# N571P032_v3 register map
File version: 1.0
Registers are 32-bit, read-write, reset 0x0 unless marked. A register's access mark holds for its fields unless they carry their own. Offsets are from the block's base; [hi:lo] are bit positions; {n}, {i} and the like mark numbered series.

## RTC — RTC Register Map
Base 0x40008000
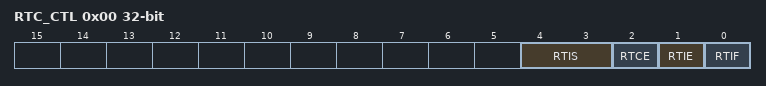
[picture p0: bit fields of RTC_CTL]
0x00 RTC_CTL — RTC Control Register
  [4:3] RTIS — RTC Timer Interval Select. These two bits select the timeout interval for the RTC.
    0=Time-out frequency is 0.25Hz,; 1=Time-out frequency is 2Hz,; 2=Time-out frequency is 8Hz,; 3=Time-out frequency is 32Hz
  [2] RTCE — RTC Enable
    0=Disable RTC function; 1=Enable RTC function
  [1] RTIE — RTC Interrupt Enable
    0=Disable the RTC interrupt; 1=Enable the RTC interrupt
  [0] RTIF — RTC Interrupt Flag. If the RTC interrupt is enabled, then the hardware will set this bit to indicate that the RTC interrupt has occurred. If the RTC interrupt is not enabled, then this bit indicates that a timeout period has elapsed. Note: This bit is cleared by writing 1 to this bit.
    0=RTC interrupt does not occur; 1=RTC interrupt occurs

## TMR — TMR Register Map
Base 0x40010000
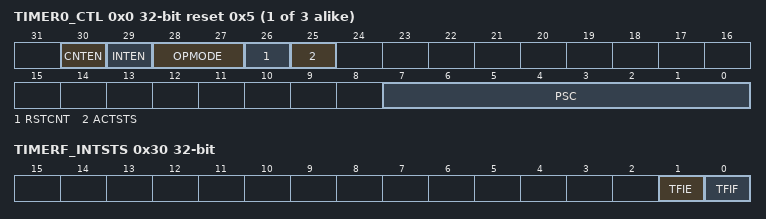
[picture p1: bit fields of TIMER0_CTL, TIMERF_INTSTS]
{0x0+0x20*i} TIMER{i}_CTL reset 0x5 (i=0..2) — Timer0 Control and Status Register
  [30] CNTEN — Counter Enable Bit
    0=Stop/Suspend counting; 1=Start counting
  [29] INTEN — Interrupt Enable Bit. If timer interrupt is enabled, the timer asserts its interrupt signal when the associated count is equal to TIMERx_CMP.
    0=Disable TIMER Interrupt; 1=Enable TIMER Interrupt
  [28:27] OPMODE — Timer Operating Mode
    0=The Timer is operating in the one-shot mode. The associated interrupt signal is generated once (if INTEN is 1) and CNTEN is automatically cleared by hardware; 1=The Timer is operating in the periodic mode. The associated interrupt signal is generated periodically (if INTEN is 1); 3=The Timer is operating in continuous counting mode. The associated interrupt signal is generated when TIMERx_CNT = TIMERx_CMP (if INTEN is 1); however, the 16-bit up-counter counts continuously without reset
  [26] RSTCNT — Counter Reset Bit. Set this bit will reset the Timer counter, pre-scale and also force CNTEN to 0.
    0=No effect; 1=Reset Timer's pre-scale counter, internal 16-bit up-counter and CNTEN bit
  [25] ACTSTS ro — Timer Active Status Bit (Read Only). This bit indicates the counter status of Timer.
    0=Timer is not active; 1=Timer is active
  [7:0] PSC — Timer Clock Prescaler
{0x4+0x20*i} TIMER{i}_CMP (i=0..2) — Timer0 Compare Register
  [15:0] CMPDAT — Timer Comparison Value. Note 1: Never set CMPDAT to 0x000 or 0x001. Timer will not function correctly. Note 2: No matter CNTEN is 0 or 1, whenever software writes a new value into this register, TIMER will restart counting by using this new value and abort previous count.
{0x8+0x20*i} TIMER{i}_INTSTS (i=0..2) — Timer0 Interrupt Status Register
  [0] TIF ro — Timer Interrupt Flag (Read Only). This bit indicates the interrupt status of Timer. TIF bit is set by hardware when the 16-bit counter matches the timer comparison value (CMPDAT). It is cleared by writing 1 to itself
    0=No effect; 1=CNT (TIMERx_CNT[15:0]) value matches the CMPDAT (TIMERx_CMP[15:0]) value
{0xC+0x20*i} TIMER{i}_CNT ro (i=0..2) — Timer0 Data Register
  [15:0] CNT — Timer Data Register. User can read this register for the current up-counter value while TIMERx_CTL.CNTEN is set to 1,
0x30 TIMERF_INTSTS — TimerF Interrupt Status Register
  [1] TFIE — TimerF Interrupt Enable
    0=Disable TimerF Interrupt; 1=Enable TimerF Interrupt
  [0] TFIF — TimerF Interrupt Flag. This bit indicates the interrupt status of TimerF. TFIF bit is set by hardware when TimerF time out. It is cleared by writing 1 to this bit.
    0=It indicates that TimerF does not time out yet; 1=It indicates that TimerF time out. The interrupt flag is set if TimerF interrupt was enabled
0x34 IR_CTL — IR Carrier Output Control Register

## WDT — WDT Register Map
Base 0x40004000
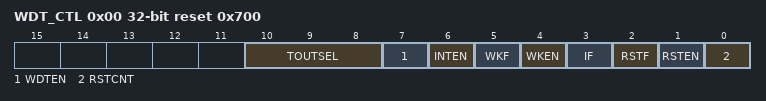
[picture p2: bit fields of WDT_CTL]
0x00 WDT_CTL reset 0x700 — Watchdog Timer Control Register
  [10:8] TOUTSEL — Watchdog Timer Interval Select. These three bits select the timeout interval for the Watchdog timer, a watchdog reset will occur 1024 clock cycles later if Watchdog timer is not reset. The WDT interrupt timeout is given by: Where WDT_CLK is the period of the Watchdog Timer clock source.
    0=24 * WDT_CLK; 1=26 * WDT_CLK; 2=28 * WDT_CLK; 3=210 * WDT_CLK; 4=212 * WDT_CLK; 5=214 * WDT_CLK; 6=216 * WDT_CLK; 7=218 * WDT_CLK
  [7] WDTEN — Watchdog Timer Enable
    0=Disable the WDT(Watchdog timer) (This action will reset the internal counter); 1=Enable the WDT(Watchdog timer)
  [6] INTEN — Watchdog Time-Out Interrupt Enable
    0=Disable the WDT time-out interrupt; 1=Enable the WDT time-out interrupt
  [5] WKF — WDT Time-Out Wake-Up Flag. If WDT causes CPU wake up from sleep or power-down mode, this bit will be set to high. Note: This bit is cleared by writing 1 to it.
    0=WDT does not cause CPU wake-up; 1=CPU wakes up from sleep or power-down mode by WDT time-out interrupt
  [4] WKEN — WDT Time-Out Wake-Up Function Control. If this bit is set to 1, while WDT time-out interrupt flag IF (WDT_CTL[3]) is generated to 1 and interrupt enable bit INTEN (WDT_CTL[6]) is enabled, the WDT time-out interrupt signal will generate a wake-up trigger event to chip.
    0=Enable the Wakeup function that WDT timeout can wake up CPU from power-down mode; 1=Disable WDT Wakeup CPU function
  [3] IF — Watchdog Timer Interrupt Flag. If the Watchdog timer interrupt is enabled, then the hardware will set this bit to indicate that the Watchdog timer interrupt has occurred. If the Watchdog timer interrupt is not enabled, then this bit indicates that a timeout period has elapsed. Note: This bit is cleared by writing 1 to this bit.
    0=Watchdog timer interrupt has not occurred; 1=Watchdog timer interrupt has occurred
  [2] RSTF — Watchdog Timer Reset Flag. When the Watchdog timer initiates a reset, the hardware will set this bit. This flag can be read by software to determine the source of reset. Software is responsible to clear it manually by writing 1 to it. If RSTEN is disabled, then the Watchdog timer has no effect on this bit. Note: This bit is cleared by writing 1 to this bit.
    0=Watchdog timer reset has not occurred; 1=Watchdog timer reset has occurred
  [1] RSTEN — Watchdog Timer Reset Enable. Setting this bit will enable the Watchdog timer reset function. Note: This function cannot work with XTL32-based clock source.
    0=Disable Watchdog timer reset function; 1=Enable Watchdog timer reset function
  [0] RSTCNT — Clear Watchdog Timer. Set this bit will clear the Watchdog timer. Note: This bit will auto clear after few clock cycles
    0=Writing 0 to this bit has no effect; 1=Reset the contents of the Watchdog timer

## APU — APU Register Map
Base 0x50008000
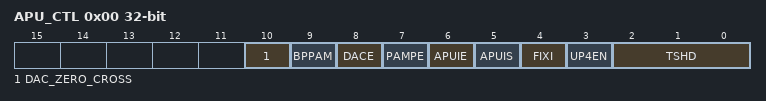
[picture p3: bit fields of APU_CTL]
0x00 APU_CTL — APU Control Register
  [10] DAC_ZERO_CROSS — DAC Output Data Cross Zero Point Flag. Note: This bit is set by hardware when DAC output data cross zero point, software can clear this bit by write 1.
    0=DAC output data doesn't cross zero point; 1=DAC output data cross zero point
  [9] BPPAM — Bypass Power Amplifier, DAC Output To Pin
    0=SPK+/DAC pin is one of power amplifier output,; 1=SPK+/DAC pin is current DAC output, no output on SPK-
  [8] DACE — DAC Enable
    0=Disable DAC function; 1=Enable DAC function
  [7] PAMPE — Power Amplifier Enable
    0=Disable PA function; 1=Enable PA function
  [6] APUIE — APU Interrupt Enable
    0=Disable the APU threshold interrupt; 1=Enable the APU threshold interrupt
  [5] APUIS — APU Interrupt Status. This flag is set by hardware when APU threshold is met. Software can clear this bit by writing a zero to it.
    0=APU threshold interrupt does not occur; 1=APU threshold interrupt occur
  [4] FIXI — DAC mode select
    0=DAC current varies by voltage (structure is same as N572F072); 1=DAC current fix (structure is same as N572F064)
  [3] UP4EN — Up sample X4 Enable. Note: Once UP4_EN set as 1, TM0CP field in TM0CPR suggest to be set as multiple times of 4 to avoid playback rate shift. Worst case of the playback rate deviation is 3/TM0CPR * 100% when least significant 2 bits of is TM0CPR b'11.
    0=Disable the APU up sample X4; 1=Enable the APU up sample X4 and filtering
  [2:0] TSHD — APU Interrupt Threshold
    {v}=Buffer {v} is read out by APU (v=0..7)
0x04 APU_VM — APU Volume Control Register
  [2:0] VOLUM — APU Volume Adjustment
    0=0 dB; 1=-3 dB; 2=-6 dB; 3=-9 dB; 4=-12 dB; 5=-15 dB; 6=-18 dB
0x0C APU_CH1DAT0 — APU Channel 1 Data Buffer Register
  [15:0] PCM1 — PCM Data Of Channel 1. This field contains 16-bit PCM data that is one of the Mixer input. User needs to take care of the effective bit of PCM because the H/W mixer output is clipped to 13 bits automatically. The data format of PCM is 2'complement.
{0x10+4i} APU_CH0DAT{i} (i=0..7) — APU Channel 0 Data Buffer Register 0
  [15:0] PCM — PCM Data Of Channel 0. This field contains 16-bit PCM data that will be sent to mixer H/W. User needs to take care of the effective bit of PCM because the H/W Mixer output is clipped to 13 bits automatically. The data format of PCM is 2'complement.
